# iosam3n register map
Registers from a debugger description file.
Registers are 32-bit, access not given, no defined reset value unless marked. A register's access mark holds for its fields unless they carry their own. Addresses are absolute; registers are grouped by the start of their names; lines under a group give offsets from that group; [hi:lo] are bit positions; {n}, {i} and the like mark numbered series; 'fields as' and 'values as' point back to an identical list; <NAME> marks a mode.

## Further device data
interrupts=NMI 0x08; HardFault 0x0C; MemManage 0x10; BusFault 0x14; UsageFault 0x18; SVC 0x2C; DebugMon 0x30; PendSV 0x38; SysTick 0x3C; SUPC 0x40; RSTC 0x44; RTC 0x48; RTT 0x4C; WDT 0x50; PMC 0x54; EFC 0x58; UART0 0x60; UART1 0x64; PIOA 0x6C; PIOB 0x70; PIOC 0x74; USART0 0x78; USART1 0x7C; TWI0 0x8C; TWI1 0x90; SPI 0x94; TC0 0x9C; TC1 0xA0; TC2 0xA4; TC3 0xA8; TC4 0xAC; TC5 0xB0; ADC 0xB4; DACC 0xB8; PWM 0xBC

## NVIC
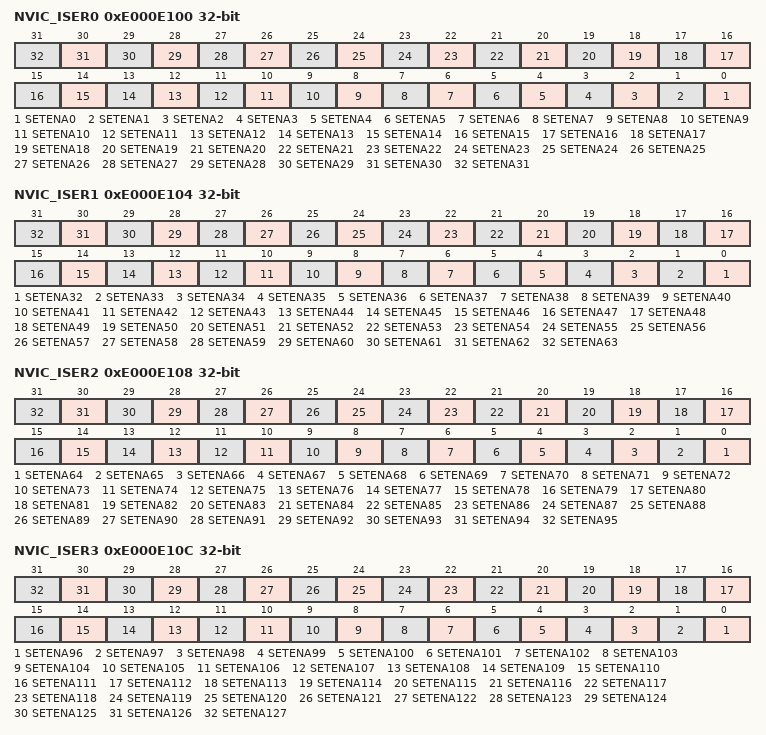
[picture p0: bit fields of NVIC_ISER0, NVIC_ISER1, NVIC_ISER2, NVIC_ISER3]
0xE000E100 NVIC_ISER0
  [n] SETENA{n} (n=0..31)
0xE000E104 NVIC_ISER1
  [n-32] SETENA{n} (n=32..63)
0xE000E108 NVIC_ISER2
  [n-64] SETENA{n} (n=64..95)
0xE000E10C NVIC_ISER3
  [n-96] SETENA{n} (n=96..127)
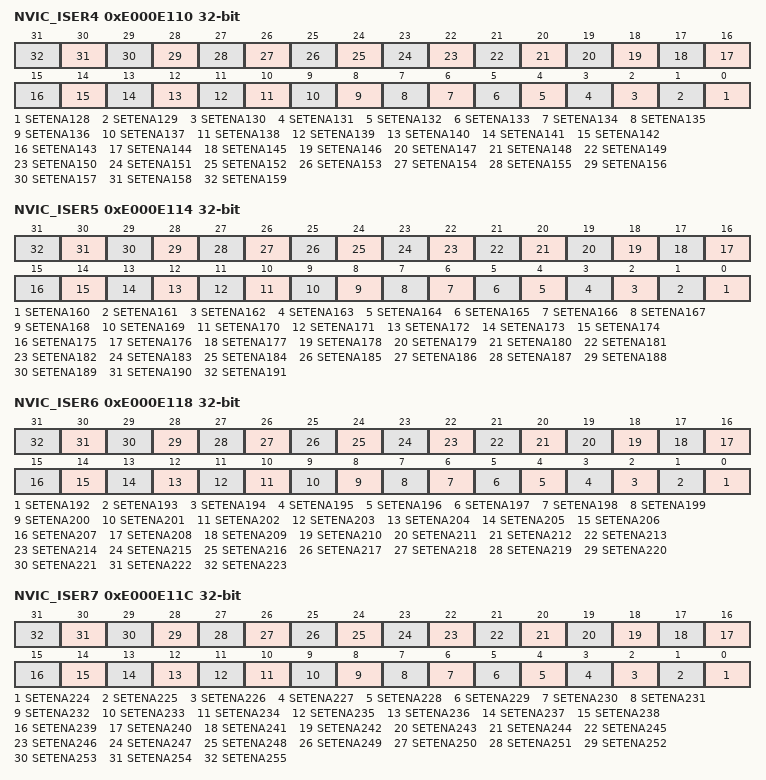
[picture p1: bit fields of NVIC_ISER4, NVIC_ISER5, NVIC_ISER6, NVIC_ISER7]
0xE000E110 NVIC_ISER4
  [n-128] SETENA{n} (n=128..159)
0xE000E114 NVIC_ISER5
  [n-160] SETENA{n} (n=160..191)
0xE000E118 NVIC_ISER6
  [n-192] SETENA{n} (n=192..223)
0xE000E11C NVIC_ISER7
  [n-224] SETENA{n} (n=224..255)
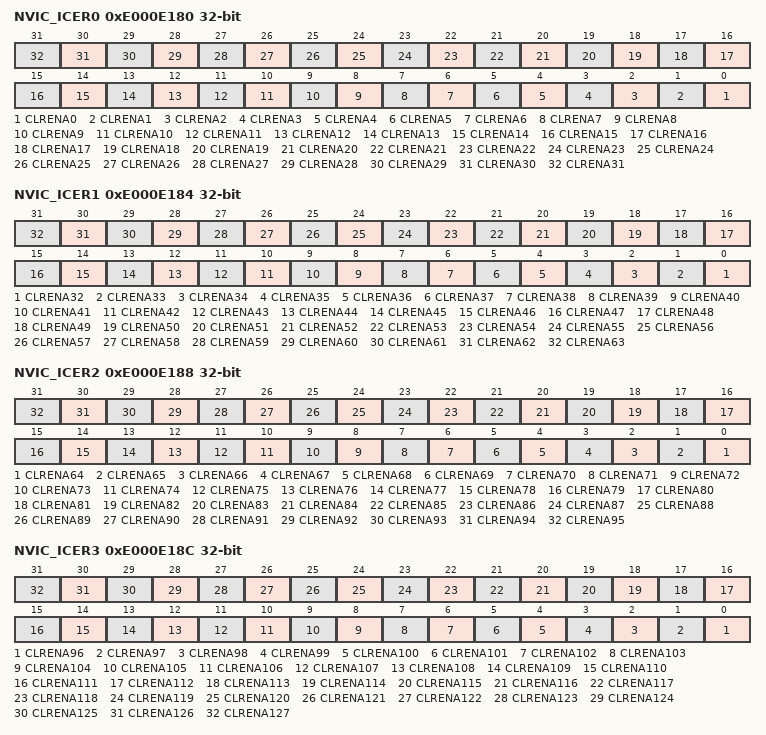
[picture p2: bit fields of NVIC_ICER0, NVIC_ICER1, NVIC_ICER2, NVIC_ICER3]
0xE000E180 NVIC_ICER0
  [n] CLRENA{n} (n=0..31)
0xE000E184 NVIC_ICER1
  [n-32] CLRENA{n} (n=32..63)
0xE000E188 NVIC_ICER2
  [n-64] CLRENA{n} (n=64..95)
0xE000E18C NVIC_ICER3
  [n-96] CLRENA{n} (n=96..127)
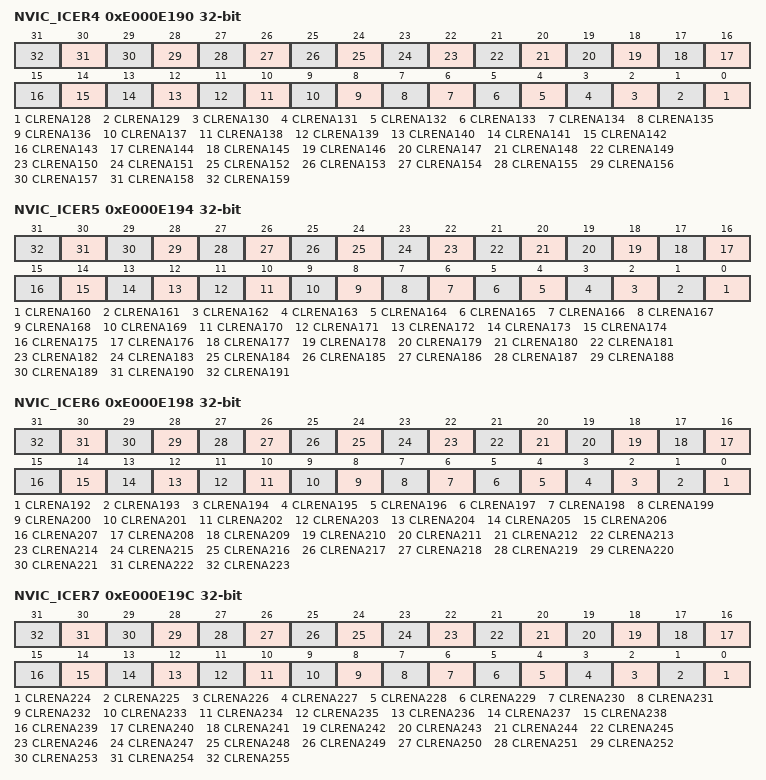
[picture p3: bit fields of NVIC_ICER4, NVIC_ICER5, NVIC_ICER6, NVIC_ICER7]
0xE000E190 NVIC_ICER4
  [n-128] CLRENA{n} (n=128..159)
0xE000E194 NVIC_ICER5
  [n-160] CLRENA{n} (n=160..191)
0xE000E198 NVIC_ICER6
  [n-192] CLRENA{n} (n=192..223)
0xE000E19C NVIC_ICER7
  [n-224] CLRENA{n} (n=224..255)
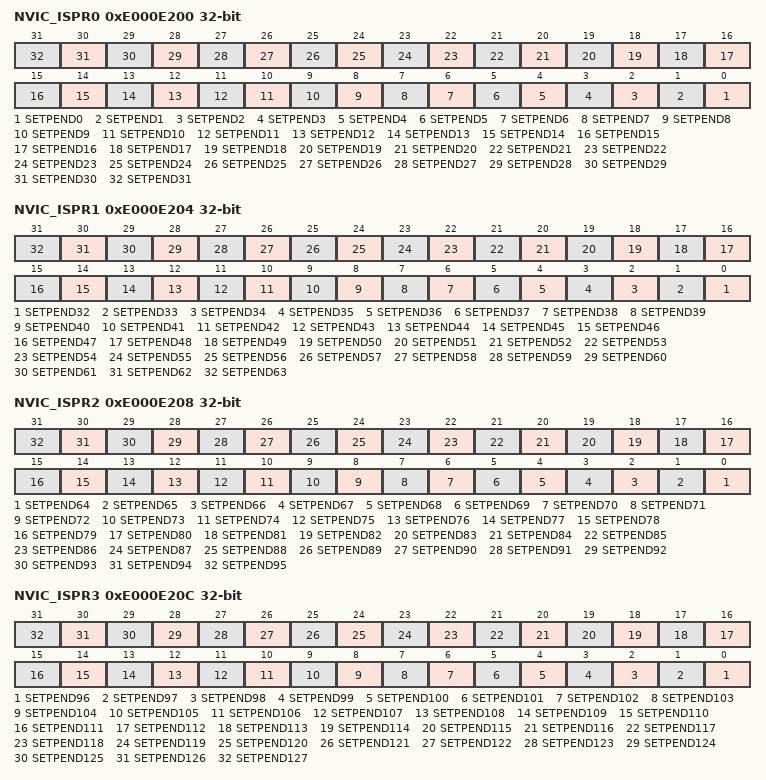
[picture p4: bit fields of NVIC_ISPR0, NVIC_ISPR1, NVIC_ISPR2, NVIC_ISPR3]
0xE000E200 NVIC_ISPR0
  [n] SETPEND{n} (n=0..31)
0xE000E204 NVIC_ISPR1
  [n-32] SETPEND{n} (n=32..63)
0xE000E208 NVIC_ISPR2
  [n-64] SETPEND{n} (n=64..95)
0xE000E20C NVIC_ISPR3
  [n-96] SETPEND{n} (n=96..127)
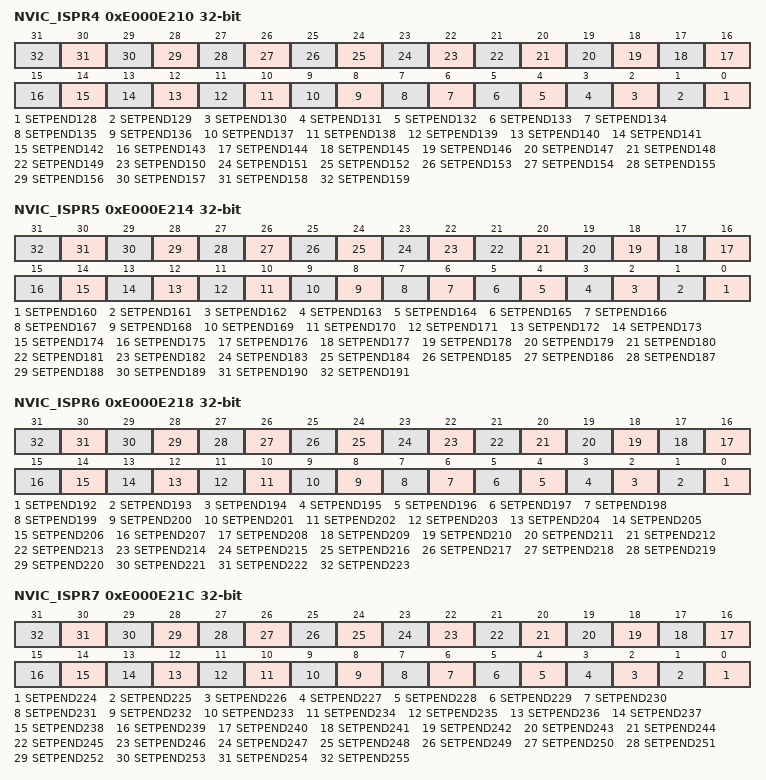
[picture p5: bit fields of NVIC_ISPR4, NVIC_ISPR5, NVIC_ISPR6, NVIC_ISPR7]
0xE000E210 NVIC_ISPR4
  [n-128] SETPEND{n} (n=128..159)
0xE000E214 NVIC_ISPR5
  [n-160] SETPEND{n} (n=160..191)
0xE000E218 NVIC_ISPR6
  [n-192] SETPEND{n} (n=192..223)
0xE000E21C NVIC_ISPR7
  [n-224] SETPEND{n} (n=224..255)
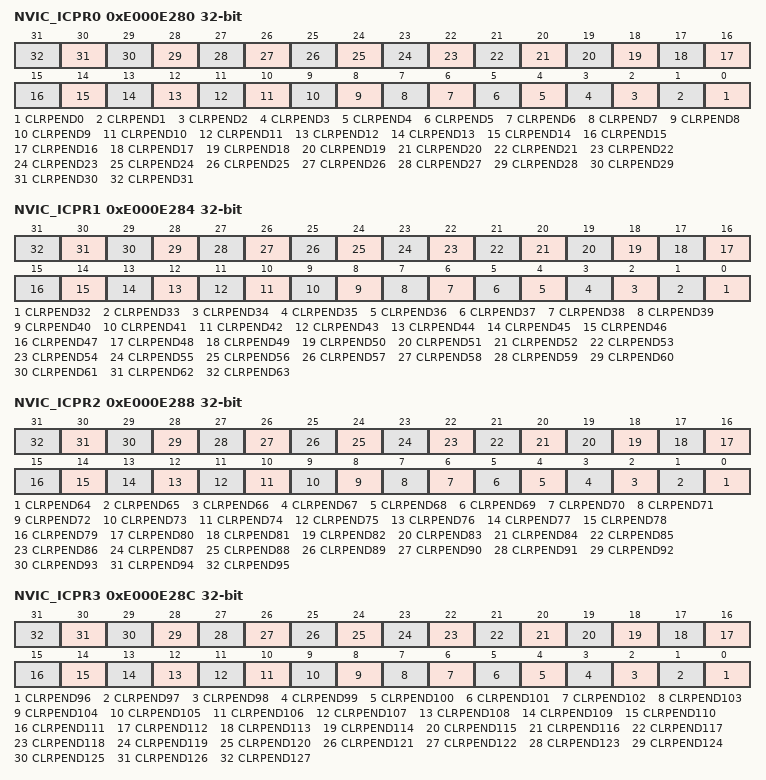
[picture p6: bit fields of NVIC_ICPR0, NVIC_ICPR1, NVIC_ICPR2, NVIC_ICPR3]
0xE000E280 NVIC_ICPR0
  [n] CLRPEND{n} (n=0..31)
0xE000E284 NVIC_ICPR1
  [n-32] CLRPEND{n} (n=32..63)
0xE000E288 NVIC_ICPR2
  [n-64] CLRPEND{n} (n=64..95)
0xE000E28C NVIC_ICPR3
  [n-96] CLRPEND{n} (n=96..127)
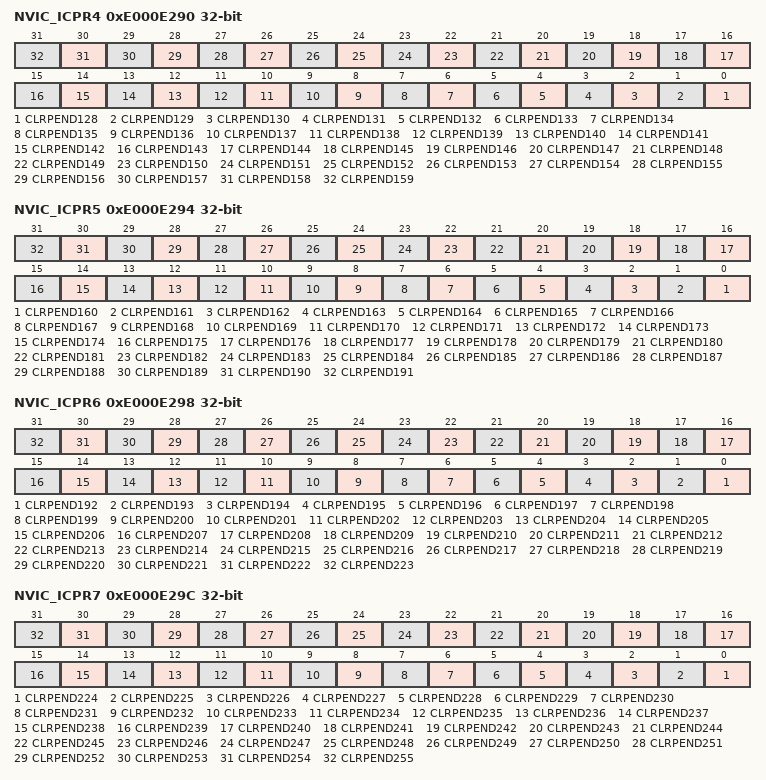
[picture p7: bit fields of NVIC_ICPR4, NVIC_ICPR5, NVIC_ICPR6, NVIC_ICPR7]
0xE000E290 NVIC_ICPR4
  [n-128] CLRPEND{n} (n=128..159)
0xE000E294 NVIC_ICPR5
  [n-160] CLRPEND{n} (n=160..191)
0xE000E298 NVIC_ICPR6
  [n-192] CLRPEND{n} (n=192..223)
0xE000E29C NVIC_ICPR7
  [n-224] CLRPEND{n} (n=224..255)
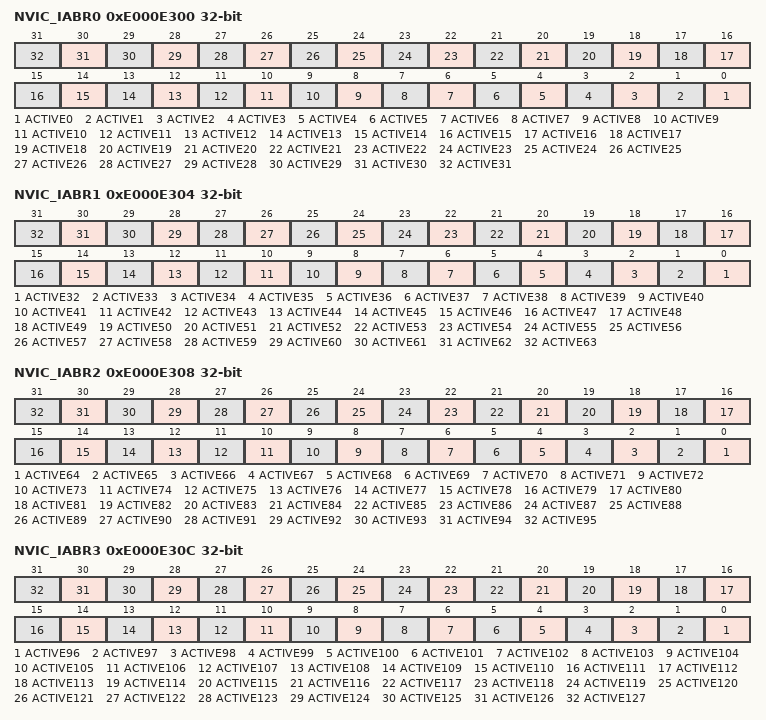
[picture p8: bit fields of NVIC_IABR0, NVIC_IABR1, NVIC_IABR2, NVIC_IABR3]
0xE000E300 NVIC_IABR0
  [n] ACTIVE{n} (n=0..31)
0xE000E304 NVIC_IABR1
  [n-32] ACTIVE{n} (n=32..63)
0xE000E308 NVIC_IABR2
  [n-64] ACTIVE{n} (n=64..95)
0xE000E30C NVIC_IABR3
  [n-96] ACTIVE{n} (n=96..127)
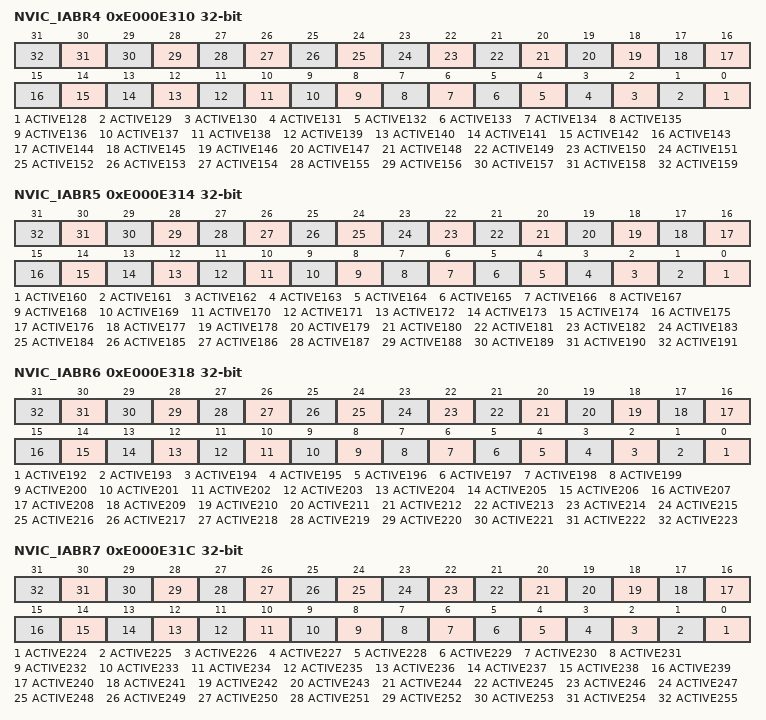
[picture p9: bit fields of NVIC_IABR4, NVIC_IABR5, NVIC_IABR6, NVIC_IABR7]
0xE000E310 NVIC_IABR4
  [n-128] ACTIVE{n} (n=128..159)
0xE000E314 NVIC_IABR5
  [n-160] ACTIVE{n} (n=160..191)
0xE000E318 NVIC_IABR6
  [n-192] ACTIVE{n} (n=192..223)
0xE000E31C NVIC_IABR7
  [n-224] ACTIVE{n} (n=224..255)
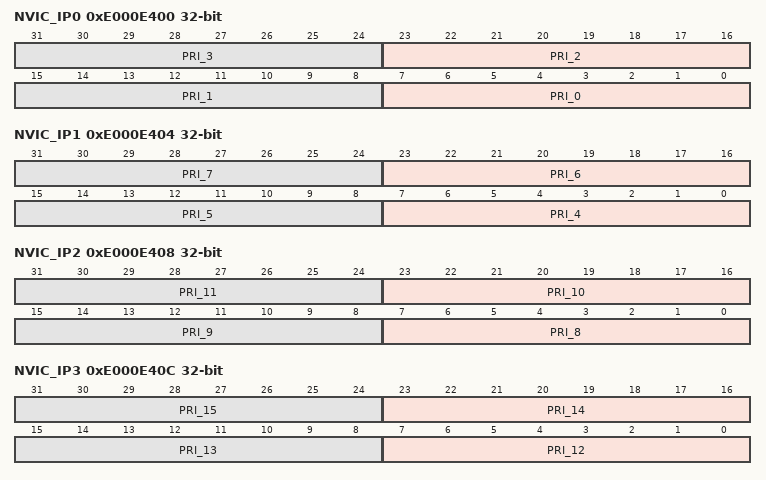
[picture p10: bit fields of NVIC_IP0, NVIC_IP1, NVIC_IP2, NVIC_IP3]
0xE000E400 NVIC_IP0
  [8n+7:8n] PRI_{n} (n=0..3)
0xE000E404 NVIC_IP1
  [8n-25:8n-32] PRI_{n} (n=4..7)
0xE000E408 NVIC_IP2
  [8n-57:8n-64] PRI_{n} (n=8..11)
0xE000E40C NVIC_IP3
  [8n-89:8n-96] PRI_{n} (n=12..15)
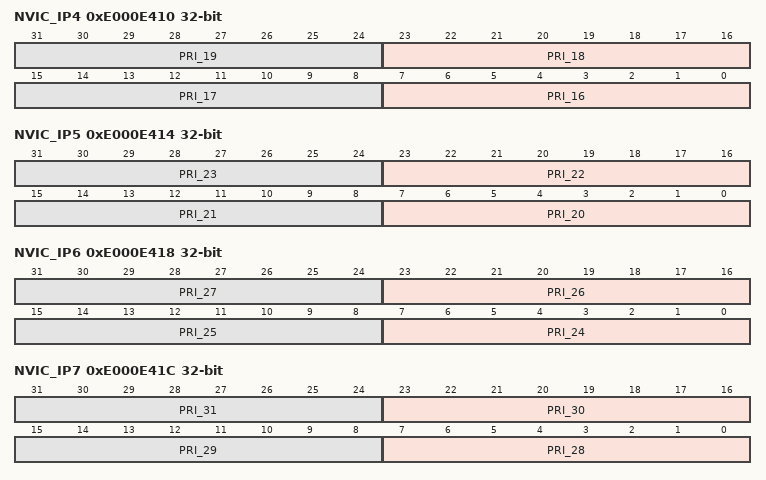
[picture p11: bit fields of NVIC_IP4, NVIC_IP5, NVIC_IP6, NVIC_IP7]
0xE000E410 NVIC_IP4
  [8n-121:8n-128] PRI_{n} (n=16..19)
0xE000E414 NVIC_IP5
  [8n-153:8n-160] PRI_{n} (n=20..23)
0xE000E418 NVIC_IP6
  [8n-185:8n-192] PRI_{n} (n=24..27)
0xE000E41C NVIC_IP7
  [8n-217:8n-224] PRI_{n} (n=28..31)
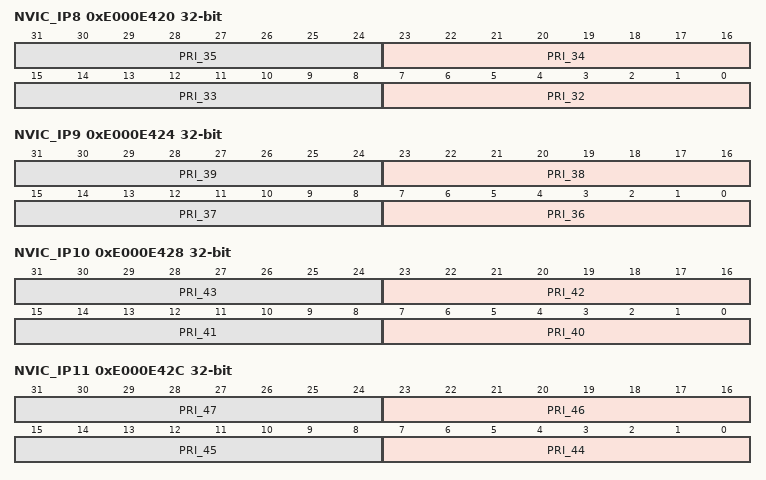
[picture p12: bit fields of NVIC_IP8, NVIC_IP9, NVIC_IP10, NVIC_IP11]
0xE000E420 NVIC_IP8
  [8n-249:8n-256] PRI_{n} (n=32..35)
0xE000E424 NVIC_IP9
  [8n-281:8n-288] PRI_{n} (n=36..39)
0xE000E428 NVIC_IP10
  [8n-313:8n-320] PRI_{n} (n=40..43)
0xE000E42C NVIC_IP11
  [8n-345:8n-352] PRI_{n} (n=44..47)
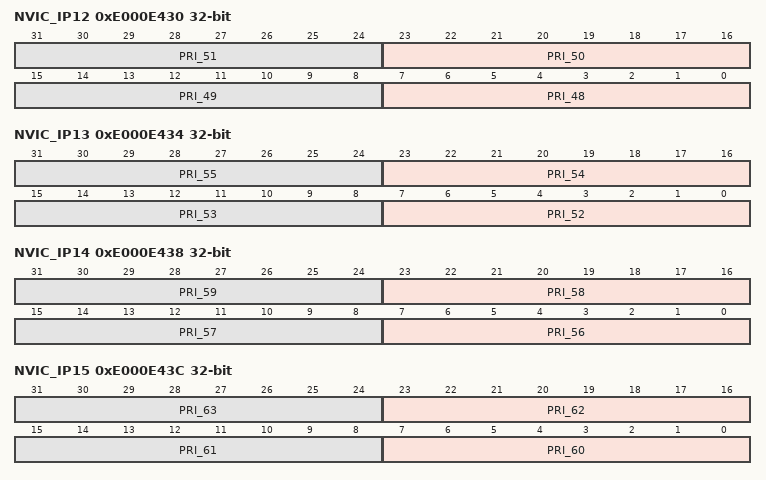
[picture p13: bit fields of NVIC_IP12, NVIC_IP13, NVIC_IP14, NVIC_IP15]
0xE000E430 NVIC_IP12
  [8n-377:8n-384] PRI_{n} (n=48..51)
0xE000E434 NVIC_IP13
  [8n-409:8n-416] PRI_{n} (n=52..55)
0xE000E438 NVIC_IP14
  [8n-441:8n-448] PRI_{n} (n=56..59)
0xE000E43C NVIC_IP15
  [8n-473:8n-480] PRI_{n} (n=60..63)
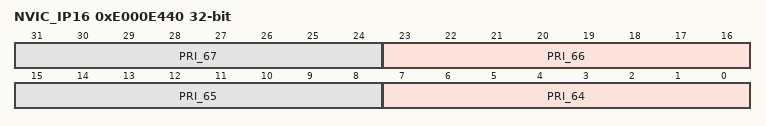
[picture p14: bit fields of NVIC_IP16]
0xE000E440 NVIC_IP16
  [8n-505:8n-512] PRI_{n} (n=64..67)
0xE000EF00 NVIC_STIR

## Notices in the file
Copyright (c) 2010, Atmel Corporation
All rights reserved.
Redistribution and use in source and binary forms, with or without
modification, are permitted provided that the following condition is met:
- Redistributions of source code must retain the above copyright notice,
this list of conditions and the disclaimer below.
Atmel's name may not be used to endorse or promote products derived from
this software without specific prior written permission.
DISCLAIMER:  THIS SOFTWARE IS PROVIDED BY ATMEL "AS IS" AND ANY EXPRESS OR
IMPLIED WARRANTIES, INCLUDING, BUT NOT LIMITED TO, THE IMPLIED WARRANTIES OF
MERCHANTABILITY, FITNESS FOR A PARTICULAR PURPOSE AND NON-INFRINGEMENT ARE
DISCLAIMED. IN NO EVENT SHALL ATMEL BE LIABLE FOR ANY DIRECT, INDIRECT,
INCIDENTAL, SPECIAL, EXEMPLARY, OR CONSEQUENTIAL DAMAGES (INCLUDING, BUT NOT
LIMITED TO, PROCUREMENT OF SUBSTITUTE GOODS OR SERVICES; LOSS OF USE, DATA,
OR PROFITS; OR BUSINESS INTERRUPTION) HOWEVER CAUSED AND ON ANY THEORY OF
LIABILITY, WHETHER IN CONTRACT, STRICT LIABILITY, OR TORT (INCLUDING
NEGLIGENCE OR OTHERWISE) ARISING IN ANY WAY OUT OF THE USE OF THIS SOFTWARE,
EVEN IF ADVISED OF THE POSSIBILITY OF SUCH DAMAGE.
